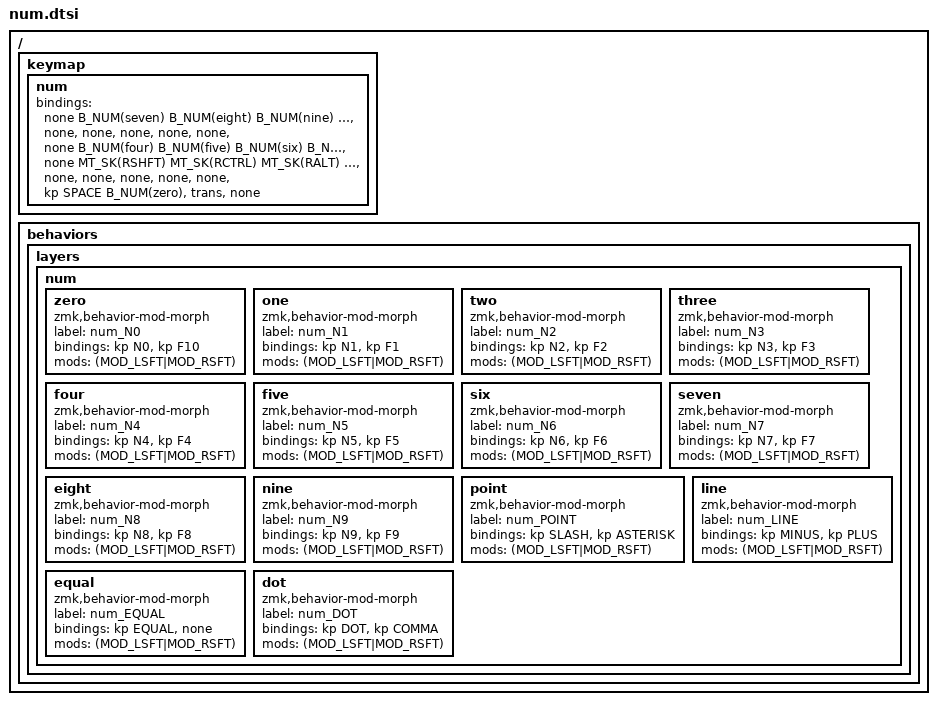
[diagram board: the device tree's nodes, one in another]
// Copyright (c) 2022 The ZMK Contributors
// SPDX-License-Identifier: MIT

#define B_NUM(key) B_LAYER(num, key)

/ {
    keymap {
        num {
            bindings = <
        // ╭──────────────┬──────────────┬──────────────┬──────────────┬──────────────╮   ╭──────────────┬──────────────┬──────────────┬──────────────┬──────────────╮
        // │              |  7           |  8           |  9           |  /*          │   │              │              │              │              │              │
             &none          B_NUM(seven)   B_NUM(eight)   B_NUM(nine)    B_NUM(point)       &none          &none          &none          &none          &none
        // ├──────────────┼──────────────┼──────────────┼──────────────┼──────────────┤   ├──────────────┼──────────────┼──────────────┼──────────────┼──────────────┤
        // │              |  4           |  5           |  6           |  -+          │   │              │  SHIFT       │  CONTROL     |  ALT         |  GUI         │
             &none          B_NUM(four)    B_NUM(five)    B_NUM(six)     B_NUM(line)        &none          MT_SK(RSHFT)   MT_SK(RCTRL)   MT_SK(RALT)    MT_SK(RGUI)
        // ├──────────────┼──────────────┼──────────────┼──────────────┼──────────────┤   ├──────────────┼──────────────┼──────────────┼──────────────┼──────────────┤
        // │  .,          |  1           |  2           |  3           |  =           │   │              │              │              │              │              │
             B_NUM(dot)     B_NUM(one)     B_NUM(two)     B_NUM(three)   B_NUM(equal)       &none          &none          &none          &none          &none
        // ╰──────────────┴──────────────┴──────────────┼──────────────┼──────────────┤   ├──────────────┼──────────────┼──────────────┴──────────────┴──────────────╯
        //                                              |  SPACE       |  0           |   |              |              |
                                                          &kp SPACE      B_NUM(zero)        &trans         &none
        //                                              ╰──────────────┴──────────────╯   ╰──────────────┴──────────────╯
            >;
        };
    };

    behaviors {
        layers {
            num {
                zero {
                    compatible = "zmk,behavior-mod-morph";
                    label = "num_N0";
                    #binding-cells = <0>;
                    bindings = <&kp N0>, <&kp F10>;
                    mods = <(MOD_LSFT|MOD_RSFT)>;
                };

                one {
                    compatible = "zmk,behavior-mod-morph";
                    label = "num_N1";
                    #binding-cells = <0>;
                    bindings = <&kp N1>, <&kp F1>;
                    mods = <(MOD_LSFT|MOD_RSFT)>;
                };

                two {
                    compatible = "zmk,behavior-mod-morph";
                    label = "num_N2";
                    #binding-cells = <0>;
                    bindings = <&kp N2>, <&kp F2>;
                    mods = <(MOD_LSFT|MOD_RSFT)>;
                };

                three {
                    compatible = "zmk,behavior-mod-morph";
                    label = "num_N3";
                    #binding-cells = <0>;
                    bindings = <&kp N3>, <&kp F3>;
                    mods = <(MOD_LSFT|MOD_RSFT)>;
                };

                four {
                    compatible = "zmk,behavior-mod-morph";
                    label = "num_N4";
                    #binding-cells = <0>;
                    bindings = <&kp N4>, <&kp F4>;
                    mods = <(MOD_LSFT|MOD_RSFT)>;
                };

                five {
                    compatible = "zmk,behavior-mod-morph";
                    label = "num_N5";
                    #binding-cells = <0>;
                    bindings = <&kp N5>, <&kp F5>;
                    mods = <(MOD_LSFT|MOD_RSFT)>;
                };

                six {
                    compatible = "zmk,behavior-mod-morph";
                    label = "num_N6";
                    #binding-cells = <0>;
                    bindings = <&kp N6>, <&kp F6>;
                    mods = <(MOD_LSFT|MOD_RSFT)>;
                };

                seven {
                    compatible = "zmk,behavior-mod-morph";
                    label = "num_N7";
                    #binding-cells = <0>;
                    bindings = <&kp N7>, <&kp F7>;
                    mods = <(MOD_LSFT|MOD_RSFT)>;
                };

                eight {
                    compatible = "zmk,behavior-mod-morph";
                    label = "num_N8";
                    #binding-cells = <0>;
                    bindings = <&kp N8>, <&kp F8>;
                    mods = <(MOD_LSFT|MOD_RSFT)>;
                };

                nine {
                    compatible = "zmk,behavior-mod-morph";
                    label = "num_N9";
                    #binding-cells = <0>;
                    bindings = <&kp N9>, <&kp F9>;
                    mods = <(MOD_LSFT|MOD_RSFT)>;
                };

                point {
                    compatible = "zmk,behavior-mod-morph";
                    label = "num_POINT";
                    #binding-cells = <0>;
                    bindings = <&kp SLASH>, <&kp ASTERISK>;
                    mods = <(MOD_LSFT|MOD_RSFT)>;
                };

                line {
                    compatible = "zmk,behavior-mod-morph";
                    label = "num_LINE";
                    #binding-cells = <0>;
                    bindings = <&kp MINUS>, <&kp PLUS>;
                    mods = <(MOD_LSFT|MOD_RSFT)>;
                };

                equal {
                    compatible = "zmk,behavior-mod-morph";
                    label = "num_EQUAL";
                    #binding-cells = <0>;
                    bindings = <&kp EQUAL>, <&none>;
                    mods = <(MOD_LSFT|MOD_RSFT)>;
                };

                dot {
                    compatible = "zmk,behavior-mod-morph";
                    label = "num_DOT";
                    #binding-cells = <0>;
                    bindings = <&kp DOT>, <&kp COMMA>;
                    mods = <(MOD_LSFT|MOD_RSFT)>;
                };
            };
        };
    };
};
